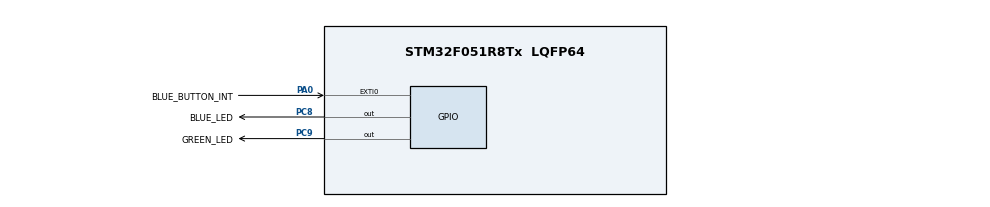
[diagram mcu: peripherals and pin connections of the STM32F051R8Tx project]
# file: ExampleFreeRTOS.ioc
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FREERTOS.INCLUDE_eTaskGetState=1
FREERTOS.INCLUDE_pcTaskGetTaskName=1
FREERTOS.INCLUDE_uxTaskGetStackHighWaterMark=1
FREERTOS.INCLUDE_vTaskCleanUpResources=1
FREERTOS.INCLUDE_vTaskDelayUntil=1
FREERTOS.INCLUDE_xQueueGetMutexHolder=1
FREERTOS.INCLUDE_xSemaphoreGetMutexHolder=1
FREERTOS.INCLUDE_xTaskAbortDelay=1
FREERTOS.INCLUDE_xTaskGetCurrentTaskHandle=1
FREERTOS.INCLUDE_xTaskGetHandle=1
FREERTOS.INCLUDE_xTimerPendFunctionCall=1
FREERTOS.Tasks01=defaultTask,0,128,StartDefaultTask,Default,NULL
FREERTOS.configGENERATE_RUN_TIME_STATS=1
FREERTOS.configTIMER_TASK_PRIORITY=3
FREERTOS.configTIMER_TASK_STACK_DEPTH=128
FREERTOS.configTOTAL_HEAP_SIZE=5120
FREERTOS.configUSE_TIMERS=1
Mcu.Family=STM32F0
Mcu.Name=STM32F051R8Tx
Mcu.Package=LQFP64
Mcu.UserConstants=test,1
NVIC.EXTI0_1_IRQn=true\:3\:0\:false\:false\:true\:true\:true
NVIC.TIM1_BRK_UP_TRG_COM_IRQn=true\:0\:0\:false\:false\:true\:false\:false
NVIC.TimeBase=TIM1_BRK_UP_TRG_COM_IRQn
NVIC.TimeBaseIP=TIM1
PA0.GPIO_Label=BLUE_BUTTON_INT
PA0.Signal=GPXTI0
PA13.Mode=Serial_Wire
PA13.Signal=SYS_SWDIO
PA14.Mode=Serial_Wire
PA14.Signal=SYS_SWCLK
PC8.GPIO_Label=BLUE_LED
PC8.Signal=GPIO_Output
PC9.GPIO_Label=GREEN_LED
PC9.Signal=GPIO_Output
ProjectManager.HeapSize=0x200
ProjectManager.StackSize=0x400
ProjectManager.TargetToolchain=SW4STM32
VP_FREERTOS_VS_ENABLE.Mode=Enabled
VP_SYS_VS_tim1.Mode=TIM1
board=custom

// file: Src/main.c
/* USER CODE BEGIN Header */
/**
  ******************************************************************************
  * @file           : main.c
  * @brief          : Main program body
  ******************************************************************************
  * This notice applies to any and all portions of this file
  * that are not between comment pairs USER CODE BEGIN and
  * USER CODE END. Other portions of this file, whether
  * inserted by the user or by software development tools
  * are owned by their respective copyright owners.
  *
  * Copyright (c) 2019 STMicroelectronics International N.V.
  * All rights reserved.
  *
  * Redistribution and use in source and binary forms, with or without
  * modification, are permitted, provided that the following conditions are met:
  *
  * 1. Redistribution of source code must retain the above copyright notice,
  *    this list of conditions and the following disclaimer.
  * 2. Redistributions in binary form must reproduce the above copyright notice,
  *    this list of conditions and the following disclaimer in the documentation
  *    and/or other materials provided with the distribution.
  * 3. Neither the name of STMicroelectronics nor the names of other
  *    contributors to this software may be used to endorse or promote products
  *    derived from this software without specific written permission.
  * 4. This software, including modifications and/or derivative works of this
  *    software, must execute solely and exclusively on microcontroller or
  *    microprocessor devices manufactured by or for STMicroelectronics.
  * 5. Redistribution and use of this software other than as permitted under
  *    this license is void and will automatically terminate your rights under
  *    this license.
  *
  * THIS SOFTWARE IS PROVIDED BY STMICROELECTRONICS AND CONTRIBUTORS "AS IS"
  * AND ANY EXPRESS, IMPLIED OR STATUTORY WARRANTIES, INCLUDING, BUT NOT
  * LIMITED TO, THE IMPLIED WARRANTIES OF MERCHANTABILITY, FITNESS FOR A
  * PARTICULAR PURPOSE AND NON-INFRINGEMENT OF THIRD PARTY INTELLECTUAL PROPERTY
  * RIGHTS ARE DISCLAIMED TO THE FULLEST EXTENT PERMITTED BY LAW. IN NO EVENT
  * SHALL STMICROELECTRONICS OR CONTRIBUTORS BE LIABLE FOR ANY DIRECT, INDIRECT,
  * INCIDENTAL, SPECIAL, EXEMPLARY, OR CONSEQUENTIAL DAMAGES (INCLUDING, BUT NOT
  * LIMITED TO, PROCUREMENT OF SUBSTITUTE GOODS OR SERVICES; LOSS OF USE, DATA,
  * OR PROFITS; OR BUSINESS INTERRUPTION) HOWEVER CAUSED AND ON ANY THEORY OF
  * LIABILITY, WHETHER IN CONTRACT, STRICT LIABILITY, OR TORT (INCLUDING
  * NEGLIGENCE OR OTHERWISE) ARISING IN ANY WAY OUT OF THE USE OF THIS SOFTWARE,
  * EVEN IF ADVISED OF THE POSSIBILITY OF SUCH DAMAGE.
  *
  ******************************************************************************
  */
/* USER CODE END Header */

#include "main.h"
#include "cmsis_os.h"

/* USER CODE BEGIN Includes */
#include "my_code.h"
/* USER CODE END Includes */

osThreadId defaultTaskHandle;

void SystemClock_Config(void);
static void MX_GPIO_Init(void);
void StartDefaultTask(void const * argument);

int main(void)
{

  /* MCU Configuration--------------------------------------------------------*/

  /* Reset of all peripherals, Initializes the Flash interface and the Systick. */
  HAL_Init();

  /* Configure the system clock */
  SystemClock_Config();

  /* Initialize all configured peripherals */
  MX_GPIO_Init();

  /* Create the thread(s) */
  /* definition and creation of defaultTask */
  osThreadDef(defaultTask, StartDefaultTask, osPriorityNormal, 0, 128);
  defaultTaskHandle = osThreadCreate(osThread(defaultTask), NULL);

  /* Start scheduler */
  osKernelStart();

  /* We should never get here as control is now taken by the scheduler */

  /* Infinite loop */
  while (1)
  {

  }
}

void SystemClock_Config(void)
{
  RCC_OscInitTypeDef RCC_OscInitStruct = {0};
  RCC_ClkInitTypeDef RCC_ClkInitStruct = {0};

  /**Initializes the CPU, AHB and APB busses clocks
  */
  RCC_OscInitStruct.OscillatorType = RCC_OSCILLATORTYPE_HSI;
  RCC_OscInitStruct.HSIState = RCC_HSI_ON;
  RCC_OscInitStruct.HSICalibrationValue = RCC_HSICALIBRATION_DEFAULT;
  RCC_OscInitStruct.PLL.PLLState = RCC_PLL_NONE;
  if (HAL_RCC_OscConfig(&RCC_OscInitStruct) != HAL_OK)
  {
    Error_Handler();
  }
  /**Initializes the CPU, AHB and APB busses clocks
  */
  RCC_ClkInitStruct.ClockType = RCC_CLOCKTYPE_HCLK|RCC_CLOCKTYPE_SYSCLK
                              |RCC_CLOCKTYPE_PCLK1;
  RCC_ClkInitStruct.SYSCLKSource = RCC_SYSCLKSOURCE_HSI;
  RCC_ClkInitStruct.AHBCLKDivider = RCC_SYSCLK_DIV1;
  RCC_ClkInitStruct.APB1CLKDivider = RCC_HCLK_DIV1;

  if (HAL_RCC_ClockConfig(&RCC_ClkInitStruct, FLASH_LATENCY_0) != HAL_OK)
  {
    Error_Handler();
  }
}

static void MX_GPIO_Init(void)
{
  GPIO_InitTypeDef GPIO_InitStruct = {0};

  /* GPIO Ports Clock Enable */
  __HAL_RCC_GPIOA_CLK_ENABLE();
  __HAL_RCC_GPIOC_CLK_ENABLE();

  /*Configure GPIO pin Output Level */
  HAL_GPIO_WritePin(GPIOC, BLUE_LED_Pin|GREEN_LED_Pin, GPIO_PIN_RESET);

  /*Configure GPIO pin : BLUE_BUTTON_INT_Pin */
  GPIO_InitStruct.Pin = BLUE_BUTTON_INT_Pin;
  GPIO_InitStruct.Mode = GPIO_MODE_IT_RISING;
  GPIO_InitStruct.Pull = GPIO_NOPULL;
  HAL_GPIO_Init(BLUE_BUTTON_INT_GPIO_Port, &GPIO_InitStruct);

  /*Configure GPIO pins : BLUE_LED_Pin GREEN_LED_Pin */
  GPIO_InitStruct.Pin = BLUE_LED_Pin|GREEN_LED_Pin;
  GPIO_InitStruct.Mode = GPIO_MODE_OUTPUT_PP;
  GPIO_InitStruct.Pull = GPIO_NOPULL;
  GPIO_InitStruct.Speed = GPIO_SPEED_FREQ_LOW;
  HAL_GPIO_Init(GPIOC, &GPIO_InitStruct);

  /* EXTI interrupt init*/
  HAL_NVIC_SetPriority(EXTI0_1_IRQn, 3, 0);
  HAL_NVIC_EnableIRQ(EXTI0_1_IRQn);

}

void StartDefaultTask(void const * argument)
{

  /* USER CODE BEGIN 5 */
	xTaskCreate((TaskFunction_t) vInitTask, "Init Task", 200, (void*)0, configMAX_PRIORITIES-4, NULL );
	vTaskDelete(NULL);
  /* Infinite loop */
  for(;;)
  {
    osDelay(1);
  }
  /* USER CODE END 5 */
}

void HAL_TIM_PeriodElapsedCallback(TIM_HandleTypeDef *htim)
{
  if (htim->Instance == TIM1) {
    HAL_IncTick();
  }
}

void Error_Handler(void)
{
  while(1)
  {
  }
}

/************************ (C) COPYRIGHT STMicroelectronics *****END OF FILE****/

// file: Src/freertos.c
/* USER CODE BEGIN Header */
/**
  ******************************************************************************
  * File Name          : freertos.c
  * Description        : Code for freertos applications
  ******************************************************************************
  * This notice applies to any and all portions of this file
  * that are not between comment pairs USER CODE BEGIN and
  * USER CODE END. Other portions of this file, whether
  * inserted by the user or by software development tools
  * are owned by their respective copyright owners.
  *
  * Copyright (c) 2019 STMicroelectronics International N.V.
  * All rights reserved.
  *
  * Redistribution and use in source and binary forms, with or without
  * modification, are permitted, provided that the following conditions are met:
  *
  * 1. Redistribution of source code must retain the above copyright notice,
  *    this list of conditions and the following disclaimer.
  * 2. Redistributions in binary form must reproduce the above copyright notice,
  *    this list of conditions and the following disclaimer in the documentation
  *    and/or other materials provided with the distribution.
  * 3. Neither the name of STMicroelectronics nor the names of other
  *    contributors to this software may be used to endorse or promote products
  *    derived from this software without specific written permission.
  * 4. This software, including modifications and/or derivative works of this
  *    software, must execute solely and exclusively on microcontroller or
  *    microprocessor devices manufactured by or for STMicroelectronics.
  * 5. Redistribution and use of this software other than as permitted under
  *    this license is void and will automatically terminate your rights under
  *    this license.
  *
  * THIS SOFTWARE IS PROVIDED BY STMICROELECTRONICS AND CONTRIBUTORS "AS IS"
  * AND ANY EXPRESS, IMPLIED OR STATUTORY WARRANTIES, INCLUDING, BUT NOT
  * LIMITED TO, THE IMPLIED WARRANTIES OF MERCHANTABILITY, FITNESS FOR A
  * PARTICULAR PURPOSE AND NON-INFRINGEMENT OF THIRD PARTY INTELLECTUAL PROPERTY
  * RIGHTS ARE DISCLAIMED TO THE FULLEST EXTENT PERMITTED BY LAW. IN NO EVENT
  * SHALL STMICROELECTRONICS OR CONTRIBUTORS BE LIABLE FOR ANY DIRECT, INDIRECT,
  * INCIDENTAL, SPECIAL, EXEMPLARY, OR CONSEQUENTIAL DAMAGES (INCLUDING, BUT NOT
  * LIMITED TO, PROCUREMENT OF SUBSTITUTE GOODS OR SERVICES; LOSS OF USE, DATA,
  * OR PROFITS; OR BUSINESS INTERRUPTION) HOWEVER CAUSED AND ON ANY THEORY OF
  * LIABILITY, WHETHER IN CONTRACT, STRICT LIABILITY, OR TORT (INCLUDING
  * NEGLIGENCE OR OTHERWISE) ARISING IN ANY WAY OUT OF THE USE OF THIS SOFTWARE,
  * EVEN IF ADVISED OF THE POSSIBILITY OF SUCH DAMAGE.
  *
  ******************************************************************************
  */
/* USER CODE END Header */

#include "FreeRTOS.h"
#include "task.h"
#include "main.h"

/* Hook prototypes */
void configureTimerForRunTimeStats(void);
unsigned long getRunTimeCounterValue(void);

/* USER CODE BEGIN 1 */
/* Functions needed when configGENERATE_RUN_TIME_STATS is on */
__weak void configureTimerForRunTimeStats(void)
{

}

__weak unsigned long getRunTimeCounterValue(void)
{
return 0;
}
/* USER CODE END 1 */

/************************ (C) COPYRIGHT STMicroelectronics *****END OF FILE****/
